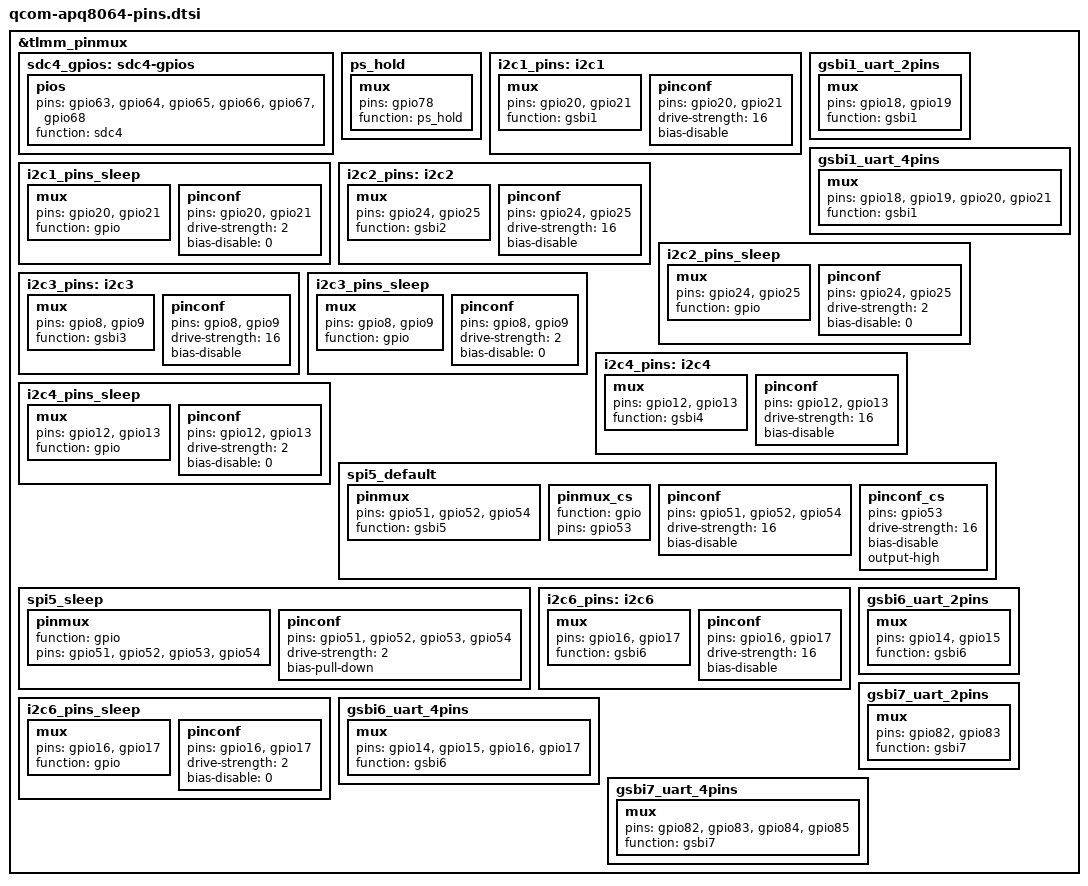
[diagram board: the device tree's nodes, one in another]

&tlmm_pinmux {
	sdc4_gpios: sdc4-gpios {
		pios {
			pins = "gpio63", "gpio64", "gpio65", "gpio66", "gpio67", "gpio68";
			function = "sdc4";
		};
	};

	ps_hold: ps_hold {
		mux {
			pins = "gpio78";
			function = "ps_hold";
		};
	};

	i2c1_pins: i2c1 {
		mux {
			pins = "gpio20", "gpio21";
			function = "gsbi1";
		};

		pinconf {
			pins = "gpio20", "gpio21";
			drive-strength = <16>;
			bias-disable;
		};
	};

	i2c1_pins_sleep: i2c1_pins_sleep {
		mux {
			pins = "gpio20", "gpio21";
			function = "gpio";
		};
		pinconf {
			pins = "gpio20", "gpio21";
			drive-strength = <2>;
			bias-disable = <0>;
		};
	};

	gsbi1_uart_2pins: gsbi1_uart_2pins {
		mux {
			pins = "gpio18", "gpio19";
			function = "gsbi1";
		};
	};

	gsbi1_uart_4pins: gsbi1_uart_4pins {
		mux {
			pins = "gpio18", "gpio19", "gpio20", "gpio21";
			function = "gsbi1";
		};
	};

	i2c2_pins: i2c2 {
		mux {
			pins = "gpio24", "gpio25";
			function = "gsbi2";
		};

		pinconf {
			pins = "gpio24", "gpio25";
			drive-strength = <16>;
			bias-disable;
		};
	};

	i2c2_pins_sleep: i2c2_pins_sleep {
		mux {
			pins = "gpio24", "gpio25";
			function = "gpio";
		};

		pinconf {
			pins = "gpio24", "gpio25";
			drive-strength = <2>;
			bias-disable = <0>;
		};
	};

	i2c3_pins: i2c3 {
		mux {
			pins = "gpio8", "gpio9";
			function = "gsbi3";
		};

		pinconf {
			pins = "gpio8", "gpio9";
			drive-strength = <16>;
			bias-disable;
		};
	};

	i2c3_pins_sleep: i2c3_pins_sleep {
		mux {
			pins = "gpio8", "gpio9";
			function = "gpio";
		};
		pinconf {
			pins = "gpio8", "gpio9";
			drive-strength = <2>;
			bias-disable = <0>;
		};
	};

	i2c4_pins: i2c4 {
		mux {
			pins = "gpio12", "gpio13";
			function = "gsbi4";
		};

		pinconf {
			pins = "gpio12", "gpio13";
			drive-strength = <16>;
			bias-disable;
		};
	};

	i2c4_pins_sleep: i2c4_pins_sleep {
		mux {
			pins = "gpio12", "gpio13";
			function = "gpio";
		};
		pinconf {
			pins = "gpio12", "gpio13";
			drive-strength = <2>;
			bias-disable = <0>;
		};
	};

	spi5_default: spi5_default {
		pinmux {
			pins = "gpio51", "gpio52", "gpio54";
			function = "gsbi5";
		};

		pinmux_cs {
			function = "gpio";
			pins = "gpio53";
		};

		pinconf {
			pins = "gpio51", "gpio52", "gpio54";
			drive-strength = <16>;
			bias-disable;
		};

		pinconf_cs {
			pins = "gpio53";
			drive-strength = <16>;
			bias-disable;
			output-high;
		};
	};

	spi5_sleep: spi5_sleep {
		pinmux {
			function = "gpio";
			pins = "gpio51", "gpio52", "gpio53", "gpio54";
		};

		pinconf {
			pins = "gpio51", "gpio52", "gpio53", "gpio54";
			drive-strength = <2>;
			bias-pull-down;
		};
	};

	i2c6_pins: i2c6 {
		mux {
			pins = "gpio16", "gpio17";
			function = "gsbi6";
		};

		pinconf {
			pins = "gpio16", "gpio17";
			drive-strength = <16>;
			bias-disable;
		};
	};

	i2c6_pins_sleep: i2c6_pins_sleep {
		mux {
			pins = "gpio16", "gpio17";
			function = "gpio";
		};
		pinconf {
			pins = "gpio16", "gpio17";
			drive-strength = <2>;
			bias-disable = <0>;
		};
	};

	gsbi6_uart_2pins: gsbi6_uart_2pins {
		mux {
			pins = "gpio14", "gpio15";
			function = "gsbi6";
		};
	};

	gsbi6_uart_4pins: gsbi6_uart_4pins {
		mux {
			pins = "gpio14", "gpio15", "gpio16", "gpio17";
			function = "gsbi6";
		};
	};

	gsbi7_uart_2pins: gsbi7_uart_2pins {
		mux {
			pins = "gpio82", "gpio83";
			function = "gsbi7";
		};
	};

	gsbi7_uart_4pins: gsbi7_uart_4pins {
		mux {
			pins = "gpio82", "gpio83", "gpio84", "gpio85";
			function = "gsbi7";
		};
	};
};
